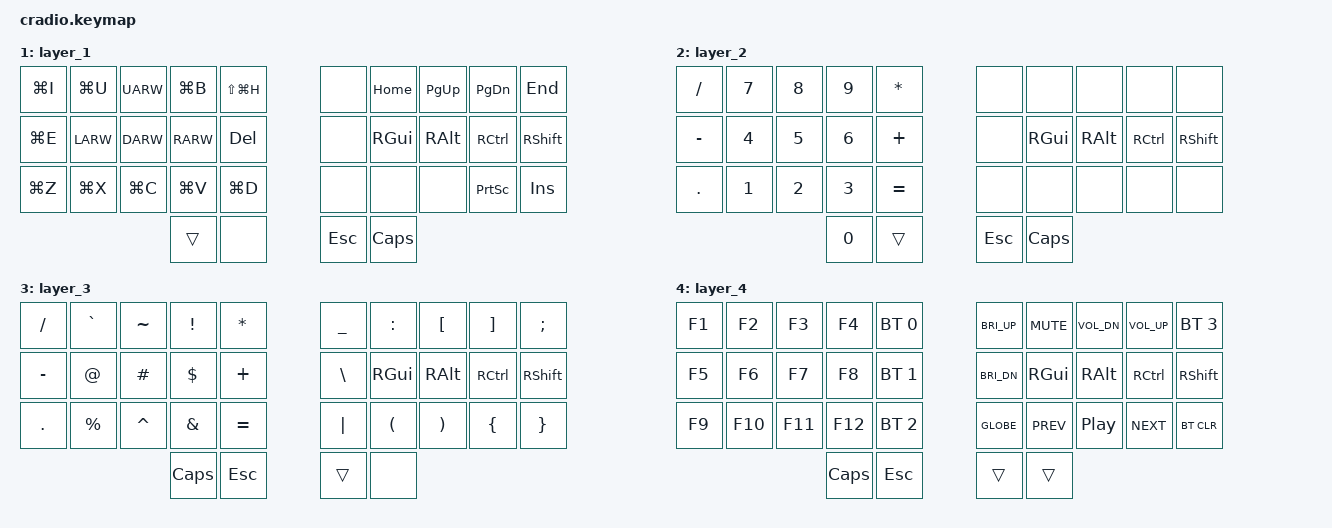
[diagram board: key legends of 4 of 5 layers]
// Copyright (c) 2022 The ZMK Contributors
// SPDX-License-Identifier: MIT

#include <behaviors.dtsi>
#include <dt-bindings/zmk/keys.h>
#include <dt-bindings/zmk/bt.h>

// Home row mods macro
#define HRML(k1,k2,k3,k4) &ht LSHFT k1  &ht LCTRL k2  &ht LALT k3  &ht LGUI k4
#define HRMR(k1,k2,k3,k4) &ht RGUI k1  &ht RALT k2  &ht RCTRL k3  &ht RSHFT k4

/ {
    behaviors {
        ht: hold_tap {
            compatible = "zmk,behavior-hold-tap";
            #binding-cells = <2>;
            flavor = "tap-preferred";
            tapping-term-ms = <220>;
            quick-tap-ms = <150>;
            require-prior-idle-ms = <100>;
            bindings = <&kp>, <&kp>;
        };
    };


    keymap {
        compatible = "zmk,keymap";
        layer_0 {
            bindings = <
        //╭──────────┬──────────┬──────────┬──────────┬──────────╮   ╭──────────┬──────────┬──────────┬──────────┬──────────╮
        //│  Q       │  W       │  F       │  P       │  B       │   │  J       │  L       │  U       │  Y       │ ' "      │
            &kp Q      &kp W      &kp F      &kp P      &kp B          &kp J      &kp L      &kp U      &kp Y      &kp SQT
        //├──────────┼──────────┼──────────┼──────────┼──────────┤   ├──────────┼──────────┼──────────┼──────────┼──────────┤
        //│  A       │  R       │  S       │  T       │  G       │   │  M       │  N       │  E       │  I       │  O       │
            HRML(A,        R,         S,         T)     &kp G          &kp M      HRMR(N,        E,         I,        O)
        //├──────────┼──────────┼──────────┼──────────┼──────────┤   ├──────────┼──────────┼──────────┼──────────┼──────────┤
        //│  Z       │  X       │  C       │  D       │  V       │   │  K       │  H       │ , <      │ . >      │ / ?      │
            &kp Z      &kp X      &kp C      &kp D      &kp V          &kp K      &kp H      &kp COMMA  &kp DOT    &kp FSLH
        //╰──────────┴──────────┴──────────┼──────────┼──────────┤   ├──────────┼──────────┼──────────┴──────────┴──────────╯
                                            &lt 1 SPACE  &lt 2 TAB    &lt 3 BSPC  &lt 4 ENTER
        //                                 ╰──────────┴──────────╯   ╰──────────┴──────────╯
            >;
        };

        layer_1 {
            bindings = <
        //╭──────────┬──────────┬──────────┬──────────┬──────────╮   ╭──────────┬──────────┬──────────┬──────────┬──────────╮
        //│ ITALIC   │ UNDERLINE│ UP       │ BOLD     │ HIGHLIGHT│   │          │ HOME     │ PAGE UP  │ PAGE DOWN│ END      │
            &kp LG(I)  &kp LG(U)  &kp UARW   &kp LG(B)  &kp LS(LG(H))  &none      &kp HOME  &kp PG_UP   &kp PG_DN  &kp END
        //├──────────┼──────────┼──────────┼──────────┼──────────┤   ├──────────┼──────────┼──────────┼──────────┼──────────┤
        //│ CODE     │ LEFT     │ DOWN     │ RIGHT    │ DELETE   │   │          │ CMD      │ ALT      │ CTRL     │ SHIFT    │
            &kp LG(E)  &kp LARW   &kp DARW   &kp RARW   &kp DEL        &none      &kp RGUI   &kp RALT   &kp RCTRL  &kp RSHIFT
        //├──────────┼──────────┼──────────┼──────────┼──────────┤   ├──────────┼──────────┼──────────┼──────────┼──────────┤
        //│ UNDO     │ CUT      │ COPY     │ PASTE    │ DUPLICATE│   │          │          │          │ PSCREEN  │ INSERT │
            &kp LG(Z)  &kp LG(X)  &kp LG(C)  &kp LG(V)  &kp LG(D)      &none      &none      &none      &kp PSCRN  &kp INS 
        //╰──────────┴──────────┴──────────┼──────────┼──────────┤   ├──────────┼──────────┼──────────┴──────────┴──────────╯
                                             &trans     &none          &kp ESC    &kp CAPS
        //                                 ╰──────────┴──────────╯   ╰──────────┴──────────╯
            >;
        };

        layer_2 {
            bindings = <
        //╭──────────┬──────────┬──────────┬──────────┬──────────╮   ╭──────────┬──────────┬──────────┬──────────┬──────────╮
        //│  /       │  7       │  8       │  9       │  *       │   │          │          │          │          │          │
            &kp SLASH  &kp N7     &kp N8     &kp N9     &kp ASTRK      &none      &none      &none      &none      &none      
        //├──────────┼──────────┼──────────┼──────────┼──────────┤   ├──────────┼──────────┼──────────┼──────────┼──────────┤
        //│  -       │  4       │  5       │  6       │  +       │   │          │ CMD      │ ALT      │ CTRL     │ SHIFT    │
            &kp MINUS  &kp N4     &kp N5     &kp N6     &kp PLUS       &none      &kp RGUI   &kp RALT   &kp RCTRL  &kp RSHIFT
        //├──────────┼──────────┼──────────┼──────────┼──────────┤   ├──────────┼──────────┼──────────┼──────────┼──────────┤
        //│  .       │  1       │  2       │  3       │  =       │   │          │          │          │          │          │
            &kp DOT    &kp N1     &kp N2     &kp N3     &kp EQUAL      &none      &none      &none      &none      &none      
        //╰──────────┴──────────┴──────────┼──────────┼──────────┤   ├──────────┼──────────┼──────────┴──────────┴──────────╯
                                             &kp N0     &trans         &kp ESC    &kp CAPS
        //                                 ╰──────────┴──────────╯   ╰──────────┴──────────╯
            >;
        };

        layer_3 {
            bindings = <
        //╭──────────┬──────────┬──────────┬──────────┬──────────╮   ╭──────────┬──────────┬──────────┬──────────┬──────────╮
        //│  /       │  `       │  ~       │  !       │  *       │   │  _       │  :       │  [       │  ]       │  ;       │
            &kp SLASH  &kp GRAVE  &kp TILDE  &kp EXCL   &kp ASTRK      &kp UNDER  &kp COLON  &kp LBKT   &kp RBKT   &kp SEMI
        //├──────────┼──────────┼──────────┼──────────┼──────────┤   ├──────────┼──────────┼──────────┼──────────┼──────────┤
        //│  -       │  @       │  #       │  $       │  +       │   │  \       │ CMD      │ ALT      │ CTRL     │ SHIFT    │
            &kp MINUS  &kp AT     &kp HASH   &kp DLLR   &kp PLUS       &kp BSLH   &kp RGUI   &kp RALT   &kp RCTRL  &kp RSHIFT
        //├──────────┼──────────┼──────────┼──────────┼──────────┤   ├──────────┼──────────┼──────────┼──────────┼──────────┤
        //│  .       │  %       │  ^       │  &       │  =       │   │  |       │  (       │  )       │  {       │  }       │
            &kp DOT    &kp PRCNT  &kp CARET  &kp AMPS   &kp EQUAL      &kp PIPE   &kp LPAR   &kp RPAR   &kp LBRC   &kp RBRC
        //╰──────────┴──────────┴──────────┼──────────┼──────────┤   ├──────────┼──────────┼──────────┴──────────┴──────────╯
                                             &kp CAPS   &kp ESC        &trans     &none
        //                                 ╰──────────┴──────────╯   ╰──────────┴──────────╯
            >;
        };

        layer_4 {
            bindings = <
        //╭──────────┬──────────┬──────────┬──────────┬──────────╮   ╭──────────┬──────────┬──────────┬──────────┬──────────╮
        //│ F1       │ F2       │ F3       │ F4       │PROFILE 0 │   │BRIGHT UP │  MUTE    │ VOL-     │ VOL+     │PROFILE 3 │
            &kp F1     &kp F2     &kp F3     &kp F4    &bt BT_SEL 0  &kp C_BRI_UP &kp C_MUTE &kp C_VOL_DN &kp C_VOL_UP &bt BT_SEL 3
        //├──────────┼──────────┼──────────┼──────────┼──────────┤   ├──────────┼──────────┼──────────┼──────────┼──────────┤
        //│ F5       │ F6       │ F7       │ F8       │PROFILE 1 │   │BRIGHT DN │ CMD      │ ALT      │ CTRL     │ SHIFT    │
            &kp F5     &kp F6     &kp F7     &kp F8    &bt BT_SEL 1  &kp C_BRI_DN &kp RGUI   &kp RALT   &kp RCTRL  &kp RSHIFT
        //├──────────┼──────────┼──────────┼──────────┼──────────┤   ├──────────┼──────────┼──────────┼──────────┼──────────┤
        //│ F9       │ F10      │ F11      │ F12      │PROFILE 2 │   │ GLOBE    │ PREVIOUS │PLAY/PAUSE│ NEXT     │ CLEAR BT │
            &kp F9     &kp F10    &kp F11    &kp F12   &bt BT_SEL 2   &kp GLOBE   &kp C_PREV &kp C_PP   &kp C_NEXT &bt BT_CLR
        //╰──────────┴──────────┴──────────┼──────────┼──────────┤   ├──────────┼──────────┼──────────┴──────────┴──────────╯
                                             &kp CAPS   &kp ESC        &trans      &trans 
        //                                 ╰──────────┴──────────╯   ╰──────────┴──────────╯
            >;
        };
    };
};
